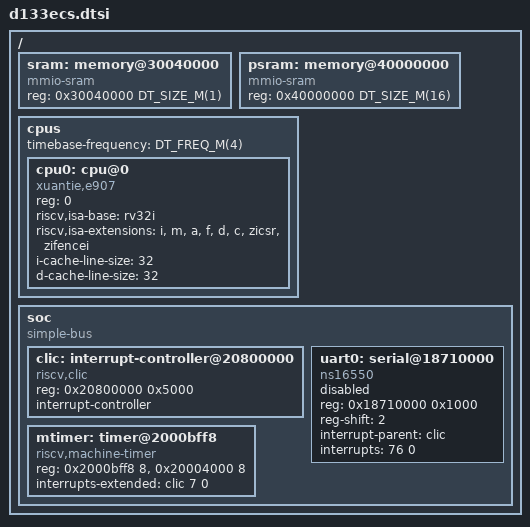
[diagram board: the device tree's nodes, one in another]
/* SPDX-License-Identifier: Apache-2.0
 * Copyright (c) 2022, Artinchip Technology Co., Ltd
 * Copyright (C) 2017-2019 Alibaba Group Holding Limited
 * Modified: register and memory-map facts from aic_soc.h/core_rv32.h/sys_freq.c/
 * Kconfig.board/gcc_aic.ld.S represented as Zephyr devicetree; no SDK runtime
 * implementation is included.
 */
#include <freq.h>
#include <mem.h>

/ {
	#address-cells = <1>;
	#size-cells = <1>;

	/*
	 * Address facts only; the board chooses where Zephyr links. SRAM_BASE is
	 * 0x30040000 and AIC_SRAM_TOTAL_SIZE defaults to 1 MiB; the SDK link script
	 * puts PSRAM_CMA at 0x40000000 and the D50T product configuration sets
	 * AIC_PSRAM_SIZE to 16 MiB. PSRAM (XSPI) is initialised by the loader - no
	 * Zephyr PSRAM driver is enabled - so a PSRAM-resident image inherits that
	 * handoff rather than proving Zephyr can drive PSRAM.
	 *
	 * No BROM node: the SDK contradicts itself on its size (aic_soc.h comment
	 * says 512KB, gcc_aic.ld.S declares 256K). Recorded in docs/provenance.yml.
	 */
	sram: memory@30040000 {
		compatible = "mmio-sram";
		reg = <0x30040000 DT_SIZE_M(1)>;
	};

	psram: memory@40000000 {
		compatible = "mmio-sram";
		reg = <0x40000000 DT_SIZE_M(16)>;
	};

	cpus {
		#address-cells = <1>;
		#size-cells = <0>;
		timebase-frequency = <DT_FREQ_M(4)>;

		cpu0: cpu@0 {
			device_type = "cpu";
			compatible = "xuantie,e907", "riscv";
			reg = <0>;
			riscv,isa-base = "rv32i";
			riscv,isa-extensions = "i", "m", "a", "f", "d", "c", "zicsr", "zifencei";
			i-cache-line-size = <32>;
			d-cache-line-size = <32>;
			status = "okay";
		};
	};

	soc {
		compatible = "simple-bus";
		#address-cells = <1>;
		#size-cells = <1>;
		ranges;

		clic: interrupt-controller@20800000 {
			compatible = "riscv,clic";
			reg = <0x20800000 0x5000>;
			#address-cells = <0>;
			#interrupt-cells = <2>;
			interrupt-controller;
		};

		mtimer: timer@2000bff8 {
			compatible = "riscv,machine-timer";
			reg = <0x2000bff8 8>, <0x20004000 8>;
			reg-names = "mtime", "mtimecmp";
			interrupts-extended = <&clic 7 0>;
		};

		uart0: serial@18710000 {
			compatible = "ns16550";
			reg = <0x18710000 0x1000>;
			reg-shift = <2>;
			interrupt-parent = <&clic>;
			interrupts = <76 0>;
			status = "disabled";
		};
	};
};
